# iCETwang-SOC register map
Vendor: 1BitSquared
Registers are 32-bit, read-write, reset 0x0 unless marked. A register's access mark holds for its fields unless they carry their own. Offsets are from the block's base; lines under a group give offsets from that group; [hi:lo] are bit positions; {n}, {i} and the like mark numbered series; 'fields as' and 'values as' point back to an identical list; <NAME> marks a mode.

## Memory map
0x81000000 UART size 0x1000000 — UART interface
0x83000000 RGBLED size 0x1000000 — RGBLED control
0x86000000 LEDSTR size 0x1000000 — RGB LED string interface
0x87000000 TIMER size 0x1000000
0x88000000 JOY size 0x1000000
0x89000000 I2C size 0x1000000

## UART — UART interface
Base 0x81000000
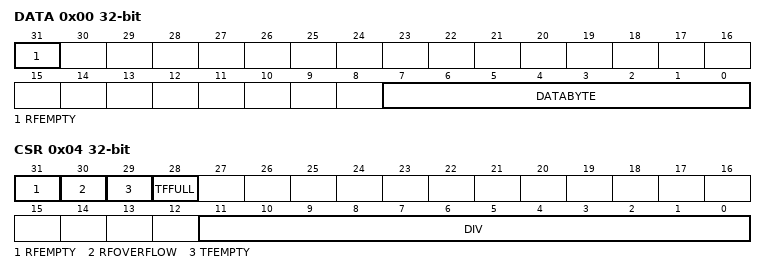
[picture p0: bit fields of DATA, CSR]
0x00 DATA — UART data in/out register. HSB 0 indicates pending data.
  [31] RFEMPTY — Receive FIFO empty flag
  [7:0] DATABYTE — The actual data input and output.
0x04 CSR — UART Config and Status Register
  [31] RFEMPTY — Receive FIFO empty flag
  [30] RFOVERFLOW — Receive FIFO overflow flag
  [29] TFEMPTY — Transmit FIFO empty flag
  [28] TFFULL — Transmit FIFO full flag
  [11:0] DIV — Baud rate clock divider

## RGBLED — RGBLED control
Base 0x83000000
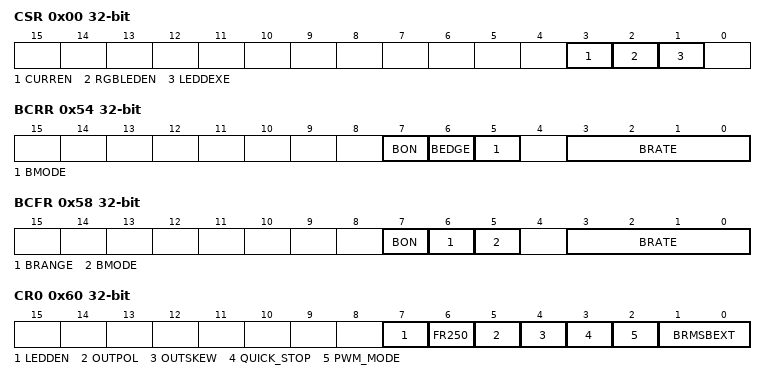
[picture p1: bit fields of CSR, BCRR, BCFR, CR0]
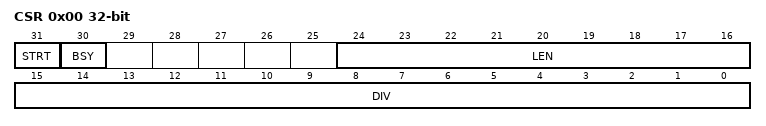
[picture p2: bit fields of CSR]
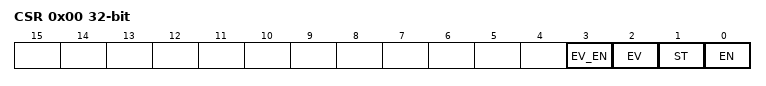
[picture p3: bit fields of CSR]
0x00 CSR — Control and Status Register
  [3] CURREN — Power up
  [2] RGBLEDEN — Enable control of the RGB LED
  [1] LEDDEXE — Enable the IP to run the blinking sequence. When low, the sequence stops at the nearest OFF state
0x44 PWRR — Pulse Width Register Red
0x48 PWRG — Pulse Width Register Green
0x4C PWRB — Pulse Width Register Blue
0x54 BCRR — Breathe Control Rise Register
  [7] BON — Breathe ON Enable
  [6] BEDGE — Breathe Edge 0= Breathe control only for ON ramp, 1= Breathe control for ON and OFF ramp
  [5] BMODE — Breathe Mode Select 0= Breathe with local rate, 1= Modulate rate based on color setting
  [3:0] BRATE — Breathe ON Rate
0x58 BCFR — Breathe Control Fall Register
  [7] BON — Breathe OFF Enable
  [6] BRANGE — Breathe Range extend for linear mode
  [5] BMODE — Breathe Mode Select 0= Breathe with local rate, 1= Modulate rate based on color setting
  [3:0] BRATE — Breathe OFF Rate
0x60 CR0 — Control Register 0
  [7] LEDDEN — LED Driver Enable
  [6] FR250 — PWM flick rate. 0= 125Hz, 1= 250Hz
  [5] OUTPOL — PWM output polarity. 0= Active high, 1= Active low
  [4] OUTSKEW — Enable PWM slew to reduce simultaneous switching noise, based on BRMSBEXT
  [3] QUICK_STOP — 0= Stop the blinking sequence wheen current ON period finishes, 1= Stop blinking immediately
  [2] PWM_MODE — 0= Linear, 1= LFSR
  [1:0] BRMSBEXT — Pre-scale register MSB extension
0x64 BR — Pre-scale Register
0x68 ONR — ON Time Register
0x6C OFR — OFF Time Register

## LEDSTR — RGB LED string interface
Base 0x86000000
0x00 CSR — Control and Status Register
  [31] STRT — Write 1 to start LED string data transmission
  [30] BSY — Reads 0 when idle and 1 when transmitting LED data
  [24:16] LEN — LED String Length
  [15:0] DIV — Clock divider
0x04 GLOB reset 0x1F — Global LED string brightness
  [4:0] GLOB

## TIMER
Base 0x87000000
0x00 CSR — Control and Status Register
  [3] EV_EN — Timer event enable
  [2] EV — Timer event, set to 1 when timer reaches 0 and EV_EN is set
  [1] ST — Timer status, 1 while timer is != 0
  [0] EN — Timer enable
0x04 LOAD — Value loaded into the timer counter when EN goes high
0x08 RELOAD — Value loaded into the timer counter when timer reaches 0
0x0C COUNTER ro — Live timer counter value

## JOY
Base 0x88000000
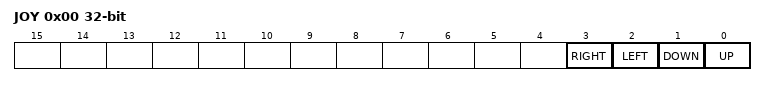
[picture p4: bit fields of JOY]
0x00 JOY — Joystick button state
  [3] RIGHT — Joystick Right
  [2] LEFT — Joystick Left
  [1] DOWN — Joystick Down
  [0] UP — Joystick Up

## I2C
Base 0x89000000
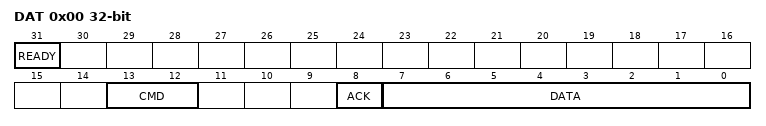
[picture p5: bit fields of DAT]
0x00 DAT — Readwrite register
  [31] READY — I2C peripheral ready
  [13:12] CMD — Set command type.
    0=START (Start condition); 1=STOP (Stop condition); 2=WRITE (Write access); 3=READ (Read access)
  [8] ACK — Write ack out, read ack in.
  [7:0] DATA — Write data to send, read received data.
